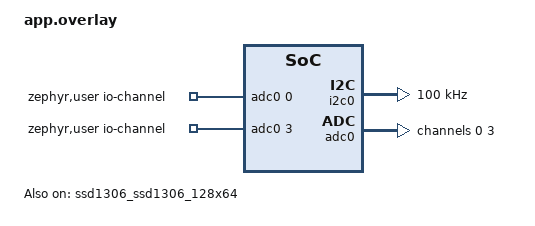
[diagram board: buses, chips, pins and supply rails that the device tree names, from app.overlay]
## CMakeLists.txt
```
cmake_minimum_required(VERSION 3.20.0)
# Must be set before find_package(Zephyr).
set(SHIELD ssd1306_128x64)
find_package(Zephyr REQUIRED HINTS $ENV{ZEPHYR_BASE})
project(zephyr_scene_player)
target_sources(app PRIVATE
    src/main.c
    src/input_thread.c
    src/display_thread.c
    src/scene_draw.c
)
```

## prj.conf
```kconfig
# GPIO/ADC for KY-023 and PRG
CONFIG_GPIO=y
CONFIG_ADC=y
CONFIG_MULTITHREADING=y

# On-board SSD1306 OLED and procedural drawings
CONFIG_I2C=y
CONFIG_DISPLAY=y
CONFIG_SSD1306=y
CONFIG_CHARACTER_FRAMEBUFFER=y
CONFIG_CHARACTER_FRAMEBUFFER_USE_DEFAULT_FONTS=y
CONFIG_HEAP_MEM_POOL_SIZE=2048

# UART terminal (COM13)
CONFIG_CONSOLE=y
CONFIG_PRINTK=y
CONFIG_LOG=y
CONFIG_LOG_DEFAULT_LEVEL=3
```

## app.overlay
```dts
#include <zephyr/dt-bindings/i2c/i2c.h>
#include <zephyr/dt-bindings/adc/adc.h>

/ {
    zephyr,user {
        /* ESP32 ADC1 hardware: GPIO36=channel 0, GPIO39=channel 3. */
        io-channels = <&adc0 0>, <&adc0 3>;
    };
};

/* Proven SSD1306 startup workaround from Example 05/06. */
&i2c0 {
    status = "okay";
    clock-frequency = <I2C_BITRATE_STANDARD>;
};
&ssd1306_ssd1306_128x64 {
    status = "okay";
    zephyr,deferred-init;
};

/* Zephyr adc0 maps to physical ESP32 ADC1. */
&adc0 {
    status = "okay";
    #address-cells = <1>;
    #size-cells = <0>;

    channel@0 {
        reg = <0>;
        zephyr,gain = "ADC_GAIN_1_4";
        zephyr,reference = "ADC_REF_INTERNAL";
        zephyr,acquisition-time = <ADC_ACQ_TIME_DEFAULT>;
        zephyr,resolution = <12>;
    };
    channel@3 {
        reg = <3>;
        zephyr,gain = "ADC_GAIN_1_4";
        zephyr,reference = "ADC_REF_INTERNAL";
        zephyr,acquisition-time = <ADC_ACQ_TIME_DEFAULT>;
        zephyr,resolution = <12>;
    };
};
```

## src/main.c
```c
/* SPDX-License-Identifier: Apache-2.0 */
/* Example 07: six-scene animation player on Heltec WiFi LoRa 32 V2. */
#include <zephyr/kernel.h>
#include <zephyr/device.h>
#include <zephyr/devicetree.h>
#include <zephyr/drivers/i2c.h>
#include <zephyr/drivers/display.h>
#include <zephyr/display/cfb.h>
#include <zephyr/sys/printk.h>
#include <errno.h>
#include "app_events.h"

#define I2C_NODE DT_NODELABEL(i2c0)
#define OLED_NODE DT_CHOSEN(zephyr_display)

#if !DT_HAS_CHOSEN(zephyr_display)
#error "Select the ssd1306_128x64 shield to provide zephyr,display"
#endif
#if !DT_NODE_HAS_PROP(OLED_NODE, zephyr_deferred_init)
#error "OLED must be deferred in app.overlay so I2C can be recovered first"
#endif

static const struct device *const i2c_dev = DEVICE_DT_GET(I2C_NODE);
static const struct device *const oled_dev = DEVICE_DT_GET(OLED_NODE);

/* Input = producer; display = consumer. Both share one statically allocated queue. */
K_MSGQ_DEFINE(app_event_queue, sizeof(struct app_event), 16, 4);

#define INPUT_STACK_SIZE 2048
#define DISPLAY_STACK_SIZE 3072
#define INPUT_PRIORITY 5
#define DISPLAY_PRIORITY 5

K_THREAD_STACK_DEFINE(input_stack, INPUT_STACK_SIZE);
K_THREAD_STACK_DEFINE(display_stack, DISPLAY_STACK_SIZE);
static struct k_thread input_thread_data;
static struct k_thread display_thread_data;

static int init_oled(void)
{
    if (!device_is_ready(i2c_dev)) { return -ENODEV; }

    /* Crucial for the Heltec V2: recovery must precede deferred SSD1306 init. */
    printk("OLED: recovering I2C bus...\n");
    int rc = i2c_recover_bus(i2c_dev);
    if (rc < 0) { return rc; }

    rc = device_init(oled_dev);
    if (rc < 0 || !device_is_ready(oled_dev)) {
        return rc < 0 ? rc : -ENODEV;
    }
    rc = display_set_pixel_format(oled_dev, PIXEL_FORMAT_MONO01);
    if (rc < 0) { return rc; }
    rc = cfb_framebuffer_init(oled_dev);
    if (rc < 0) { return rc; }
    rc = cfb_framebuffer_clear(oled_dev, false);
    if (rc < 0) { return rc; }
    rc = display_blanking_off(oled_dev);
    if (rc < 0) { return rc; }
    printk("OLED: ready\n");
    return 0;
}

int main(void)
{
    printk("\n=================================\n");
    printk(" Example 07: OLED Scene Player\n");
    printk("=================================\n");

    int rc = init_oled();
    if (rc < 0) {
        printk("ERROR: OLED initialization: %d\n", rc);
        return rc;
    }
    rc = input_thread_init();
    if (rc < 0) {
        printk("ERROR: joystick initialization: %d\n", rc);
        return rc;
    }

    /* Display starts first and renders the help screen. */
    k_thread_create(&display_thread_data, display_stack,
                    K_THREAD_STACK_SIZEOF(display_stack), display_thread_entry,
                    NULL, NULL, NULL, DISPLAY_PRIORITY, 0, K_NO_WAIT);
    k_thread_create(&input_thread_data, input_stack,
                    K_THREAD_STACK_SIZEOF(input_stack), input_thread_entry,
                    NULL, NULL, NULL, INPUT_PRIORITY, 0, K_NO_WAIT);

    printk("APP: two threads running; PRG=open/back, SW=play/pause\n");
    return 0;
}
```

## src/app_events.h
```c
/* SPDX-License-Identifier: Apache-2.0 */
#ifndef APP_EVENTS_H_
#define APP_EVENTS_H_

#include <zephyr/kernel.h>

/* Producer: input_thread.c; consumer: display_thread.c. */
enum app_event_type
{
    APP_EVENT_TOGGLE_HELP,       /* Onboard PRG */
    APP_EVENT_CATEGORY_PREVIOUS, /* Joystick up */
    APP_EVENT_CATEGORY_NEXT,     /* Joystick down */
    APP_EVENT_SCENE_PREVIOUS,    /* Joystick left */
    APP_EVENT_SCENE_NEXT,        /* Joystick right */
    APP_EVENT_SELECT,            /* Joystick SW: play / pause / resume */
};

struct app_event
{
    enum app_event_type type;
    uint32_t timestamp_ms;
};

/* Created exactly once in main.c using K_MSGQ_DEFINE(). */
extern struct k_msgq app_event_queue;

int input_thread_init(void);
void input_thread_entry(void* arg1, void* arg2, void* arg3);
void display_thread_entry(void* arg1, void* arg2, void* arg3);

#endif /* APP_EVENTS_H_ */
```

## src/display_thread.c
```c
/* SPDX-License-Identifier: Apache-2.0 */
/* One OLED-owner UI thread. Never blocks for an entire animation. */
#include <zephyr/kernel.h>
#include <zephyr/device.h>
#include <zephyr/devicetree.h>
#include <zephyr/display/cfb.h>
#include <zephyr/sys/printk.h>
#include <errno.h>
#include <stdbool.h>
#include <stddef.h>
#include <stdint.h>
#include <stdio.h>
#include <string.h>
#include "app_events.h"
#include "scene_draw.h"

#define OLED_NODE         DT_CHOSEN(zephyr_display)
#define FRAME_INTERVAL_MS 200 /* ~5 fps; conservative for 100-kHz I2C */
#define MAX_EVENT_WAIT_MS 50
#define SCREEN_W          128

static const struct device* const display = DEVICE_DT_GET(OLED_NODE);

enum page
{
    PAGE_HELP,
    PAGE_BROWSER,
    PAGE_PLAYING,
    PAGE_PAUSED
};

struct ui_state
{
    enum page page;
    enum scene_category category;
    size_t scene_index;
    uint32_t frame;
    int64_t next_frame_ms;
    bool dirty;
};

static uint8_t font_width  = 8U;
static uint8_t font_height = 8U;

#define UI_CHECK(expr)    \
    do                    \
    {                     \
        int rc_ = (expr); \
        if(rc_ < 0)       \
        {                 \
            return rc_;   \
        }                 \
    } while(0)

static int ui_line(int x0, int y0, int x1, int y1)
{
    const struct cfb_position a = { x0, y0 };
    const struct cfb_position b = { x1, y1 };
    return cfb_draw_line(display, &a, &b);
}

/* Width clipping prevents long scene labels from reaching outside the display. */
static int ui_text(const char* str, int x, int y)
{
    char clipped[25];
    size_t max_chars;
    if(x < 0 || x >= SCREEN_W || y < 0 || y + font_height > 64)
    {
        return -EINVAL;
    }
    max_chars = (SCREEN_W - (size_t)x) / font_width;
    if(max_chars >= sizeof(clipped))
    {
        max_chars = sizeof(clipped) - 1U;
    }
    size_t n = strlen(str);
    if(n > max_chars)
    {
        n = max_chars;
    }
    memcpy(clipped, str, n);
    clipped[n] = '\0';
    return cfb_print(display, clipped, (int16_t)x, (int16_t)y);
}

static void select_compact_font(void)
{
    int count = cfb_get_numof_fonts(display);
    for(int i = 0; i < count; ++i)
    {
        uint8_t w = 0, h = 0;
        if(cfb_get_font_size(display, (uint8_t)i, &w, &h) == 0 && w > 0 && w <= 8 &&
           h > 0 && h <= 8 && cfb_framebuffer_set_font(display, (uint8_t)i) == 0)
        {
            font_width  = w;
            font_height = h;
            printk("DISPLAY: CFB font %dx%d\n", w, h);
            return;
        }
    }
    printk("DISPLAY: no compact font found; default font in use\n");
}

static int draw_help(void)
{
    const struct cfb_position center = { 64, 34 };
    UI_CHECK(ui_text("SCENE PLAYER", 0, 0));
    UI_CHECK(ui_line(0, 10, 127, 10));

    UI_CHECK(ui_line(64, 14, 64, 23));
    UI_CHECK(ui_line(64, 14, 58, 20));
    UI_CHECK(ui_line(64, 14, 70, 20));
    UI_CHECK(ui_text("CAT", 77, 15));

    UI_CHECK(ui_line(40, 35, 29, 35));
    UI_CHECK(ui_line(29, 35, 35, 29));
    UI_CHECK(ui_line(29, 35, 35, 41));
    UI_CHECK(ui_text("PREV", 0, 31));

    UI_CHECK(cfb_draw_circle(display, &center, 9));
    UI_CHECK(ui_text("SW", 58, 30));

    UI_CHECK(ui_line(87, 35, 98, 35));
    UI_CHECK(ui_line(98, 35, 92, 29));
    UI_CHECK(ui_line(98, 35, 92, 41));
    UI_CHECK(ui_text("NEXT", 102, 31));

    UI_CHECK(ui_line(64, 45, 64, 53));
    UI_CHECK(ui_line(64, 53, 58, 47));
    UI_CHECK(ui_line(64, 53, 70, 47));
    UI_CHECK(ui_text("CAT", 77, 45));
    UI_CHECK(ui_text("PRG: OPEN/BACK", 0, 56));
    return 0;
}

static enum scene_id selected_scene(const struct ui_state* ui)
{
    return scene_category_get(ui->category, ui->scene_index);
}

static int draw_browser(const struct ui_state* ui)
{
    enum scene_id id = selected_scene(ui);
    char heading[25];
    int n = snprintf(heading, sizeof(heading), "%s %u/%u",
                     scene_category_name(ui->category),
                     (unsigned int)(ui->scene_index + 1U),
                     (unsigned int)scene_category_count(ui->category));
    if(n < 0)
    {
        return -EINVAL;
    }
    UI_CHECK(scene_draw(display, id, 0)); /* Preview first frame */
    UI_CHECK(ui_text(heading, 0, 0));
    UI_CHECK(ui_text(scene_name(id), 0, 56));
    return 0;
}

static int ui_render(const struct ui_state* ui)
{
    UI_CHECK(cfb_framebuffer_clear(display, false));
    switch(ui->page)
    {
        case PAGE_HELP:
            UI_CHECK(draw_help());
            break;
        case PAGE_BROWSER:
            UI_CHECK(draw_browser(ui));
            break;
        case PAGE_PLAYING:
        case PAGE_PAUSED:
            UI_CHECK(scene_draw(display, selected_scene(ui), ui->frame));
            if(ui->page == PAGE_PAUSED)
            {
                UI_CHECK(ui_text("PAUSED", 0, 0));
                UI_CHECK(ui_text("SW: RESUME", 0, 56));
            }
            break;
        default:
            return -EINVAL;
    }
    return cfb_framebuffer_finalize(display);
}

/* A PRG press always returns to the help page from anywhere except help. */
static void handle_event(struct ui_state* ui, enum app_event_type ev)
{
    if(ev == APP_EVENT_TOGGLE_HELP)
    {
        ui->page  = (ui->page == PAGE_HELP) ? PAGE_BROWSER : PAGE_HELP;
        ui->dirty = true;
        return;
    }
    if(ui->page == PAGE_HELP)
    {
        return;
    }

    if(ev == APP_EVENT_SELECT)
    {
        switch(ui->page)
        {
            case PAGE_BROWSER:
                ui->page          = PAGE_PLAYING;
                ui->frame         = 0;
                ui->next_frame_ms = k_uptime_get() + FRAME_INTERVAL_MS;
                break;
            case PAGE_PLAYING:
                ui->page = PAGE_PAUSED;
                break;
            case PAGE_PAUSED:
                ui->page          = PAGE_PLAYING;
                ui->next_frame_ms = k_uptime_get() + FRAME_INTERVAL_MS;
                break;
            default:
                break;
        }
        ui->dirty = true;
        return;
    }
    if(ui->page != PAGE_BROWSER)
    {
        return;
    }

    switch(ev)
    {
        case APP_EVENT_CATEGORY_PREVIOUS:
            ui->category = (enum scene_category)(
            (ui->category + SCENE_CATEGORY_COUNT - 1) % SCENE_CATEGORY_COUNT);
            ui->scene_index = 0;
            ui->dirty       = true;
            break;
        case APP_EVENT_CATEGORY_NEXT:
            ui->category = (enum scene_category)((ui->category + 1) % SCENE_CATEGORY_COUNT);
            ui->scene_index = 0;
            ui->dirty       = true;
            break;
        case APP_EVENT_SCENE_PREVIOUS:
            ui->scene_index =
            (ui->scene_index + scene_category_count(ui->category) - 1U) %
            scene_category_count(ui->category);
            ui->dirty = true;
            break;
        case APP_EVENT_SCENE_NEXT:
            ui->scene_index = (ui->scene_index + 1U) % scene_category_count(ui->category);
            ui->dirty = true;
            break;
        default:
            break;
    }
}

void display_thread_entry(void* arg1, void* arg2, void* arg3)
{
    ARG_UNUSED(arg1);
    ARG_UNUSED(arg2);
    ARG_UNUSED(arg3);
    struct ui_state ui = {
        .page          = PAGE_HELP,
        .category      = SCENE_CAT_SPACE,
        .scene_index   = 0,
        .frame         = 0,
        .next_frame_ms = 0,
        .dirty         = true,
    };
    select_compact_font();
    printk("DISPLAY: scene player started (help screen)\n");

    while(true)
    {
        int64_t now = k_uptime_get();
        int wait_ms = MAX_EVENT_WAIT_MS;
        if(ui.page == PAGE_PLAYING)
        {
            int64_t remaining = ui.next_frame_ms - now;
            if(remaining <= 0)
            {
                wait_ms = 0;
            }
            else if(remaining < wait_ms)
            {
                wait_ms = (int)remaining;
            }
        }

        struct app_event msg;
        if(k_msgq_get(&app_event_queue, &msg, K_MSEC(wait_ms)) == 0)
        {
            handle_event(&ui, msg.type);
        }

        now = k_uptime_get();
        if(ui.page == PAGE_PLAYING && now >= ui.next_frame_ms)
        {
            ui.frame++;
            ui.next_frame_ms = now + FRAME_INTERVAL_MS;
            ui.dirty         = true;
        }
        if(ui.dirty)
        {
            int rc = ui_render(&ui);
            if(rc != 0)
            {
                printk("DISPLAY: render error %d\n", rc);
            }
            ui.dirty = false;
        }
    }
}
```

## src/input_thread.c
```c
/* SPDX-License-Identifier: Apache-2.0 */
/* KY-023 joystick + onboard PRG GPIO0. One event per deflection/press. */
#include <zephyr/kernel.h>
#include <zephyr/device.h>
#include <zephyr/devicetree.h>
#include <zephyr/drivers/adc.h>
#include <zephyr/drivers/gpio.h>
#include <zephyr/sys/printk.h>
#include <errno.h>
#include <stdbool.h>
#include <stdint.h>
#include "app_events.h"

#define USER_NODE DT_PATH(zephyr_user)
#define PRG_NODE DT_ALIAS(sw0)
#define GPIO_NODE DT_NODELABEL(gpio0)

#if !DT_NODE_EXISTS(USER_NODE)
#error "app.overlay must declare zephyr,user { io-channels = <&adc0 0>, <&adc0 3>; };"
#endif
#if !DT_NODE_EXISTS(PRG_NODE)
#error "Board requires sw0 (onboard PRG button) alias"
#endif

/* Connections: VRx=GPIO36 / ADC1_CH0, VRy=GPIO39 / ADC1_CH3, SW=GPIO13. */
#define JOY_SW_PIN 13
#define POLL_MS 50
#define BUTTON_STABLE_SAMPLES 3
#define JOY_LOW 1100
#define JOY_HIGH 3200
#define JOY_CENTER_MIN 1500
#define JOY_CENTER_MAX 2700

/* Change to 1 if your joystick is mounted in the opposite orientation. */
#define JOY_REVERSE_X 0
#define JOY_REVERSE_Y 0

static const struct adc_dt_spec x_axis = ADC_DT_SPEC_GET_BY_IDX(USER_NODE, 0);
static const struct adc_dt_spec y_axis = ADC_DT_SPEC_GET_BY_IDX(USER_NODE, 1);
static const struct gpio_dt_spec prg = GPIO_DT_SPEC_GET(PRG_NODE, gpios);
static const struct device *const port0 = DEVICE_DT_GET(GPIO_NODE);

struct key_debounce {
    bool last_sample;
    bool pressed;
    uint8_t stable_count;
};

static struct key_debounce prg_key;
static struct key_debounce sw_key;

static void send_event(enum app_event_type type)
{
    struct app_event msg = { .type = type, .timestamp_ms = k_uptime_get_32() };
    if (k_msgq_put(&app_event_queue, &msg, K_NO_WAIT) != 0) {
        printk("INPUT: queue full, event %d dropped\n", (int)type);
    }
}

/* True only on the debounced RELEASED->PRESSED transition. */
static bool just_pressed(struct key_debounce *key, bool pressed)
{
    if (key->last_sample != pressed) {
        key->last_sample = pressed;
        key->stable_count = 1;
    } else if (key->stable_count < BUTTON_STABLE_SAMPLES) {
        key->stable_count++;
    }
    if (key->stable_count >= BUTTON_STABLE_SAMPLES && key->pressed != pressed) {
        key->pressed = pressed;
        return pressed;
    }
    return false;
}

static int read_adc(const struct adc_dt_spec *channel, int16_t *result)
{
    int16_t raw = 0;
    struct adc_sequence sequence = {
        .buffer = &raw,
        .buffer_size = sizeof(raw),
    };
    int rc = adc_sequence_init_dt(channel, &sequence);
    if (rc != 0) { return rc; }
    rc = adc_read_dt(channel, &sequence);
    if (rc == 0) { *result = raw; }
    return rc;
}

int input_thread_init(void)
{
    if (!adc_is_ready_dt(&x_axis) || !adc_is_ready_dt(&y_axis) ||
        !gpio_is_ready_dt(&prg) || !device_is_ready(port0)) {
        return -ENODEV;
    }
    int rc = adc_channel_setup_dt(&x_axis);
    if (rc != 0) { return rc; }
    rc = adc_channel_setup_dt(&y_axis);
    if (rc != 0) { return rc; }
    rc = gpio_pin_configure_dt(&prg, GPIO_INPUT);
    if (rc != 0) { return rc; }
    rc = gpio_pin_configure(port0, JOY_SW_PIN, GPIO_INPUT | GPIO_PULL_UP);
    if (rc != 0) { return rc; }
    printk("INPUT: joystick ADC and SW, PRG ready\n");
    return 0;
}

void input_thread_entry(void *arg1, void *arg2, void *arg3)
{
    ARG_UNUSED(arg1);
    ARG_UNUSED(arg2);
    ARG_UNUSED(arg3);

    bool joystick_armed = true;
    int16_t x, y;

    while (true) {
        if (read_adc(&x_axis, &x) == 0 && read_adc(&y_axis, &y) == 0) {
            /* A shared latch rejects diagonal double-events. */
            bool centered = (x >= JOY_CENTER_MIN && x <= JOY_CENTER_MAX &&
                             y >= JOY_CENTER_MIN && y <= JOY_CENTER_MAX);
            if (centered) {
                joystick_armed = true;
            } else if (joystick_armed) {
                enum app_event_type type;
                bool has_event = true;
                int dx = (x > 2048) ? (x - 2048) : (2048 - x);
                int dy = (y > 2048) ? (y - 2048) : (2048 - y);
                if (dx >= dy && (x < JOY_LOW || x > JOY_HIGH)) {
                    bool right = (x > JOY_HIGH);
                    if (JOY_REVERSE_X) { right = !right; }
                    type = right ? APP_EVENT_SCENE_NEXT : APP_EVENT_SCENE_PREVIOUS;
                } else if (y < JOY_LOW || y > JOY_HIGH) {
                    bool down = (y > JOY_HIGH);
                    if (JOY_REVERSE_Y) { down = !down; }
                    type = down ? APP_EVENT_CATEGORY_NEXT : APP_EVENT_CATEGORY_PREVIOUS;
                } else {
                    has_event = false;
                }
                if (has_event) {
                    send_event(type);
                    joystick_armed = false;
                }
            }
        }

        int p = gpio_pin_get_dt(&prg);
        /* GPIO_ACTIVE_LOW in board DTS: logical 1 means pressed. */
        if (p >= 0 && just_pressed(&prg_key, p != 0)) {
            send_event(APP_EVENT_TOGGLE_HELP);
        }

        int s = gpio_pin_get_raw(port0, JOY_SW_PIN);
        /* Physical KY-023 switch connects SW to GND on press. */
        if (s >= 0 && just_pressed(&sw_key, s == 0)) {
            send_event(APP_EVENT_SELECT);
        }
        k_sleep(K_MSEC(POLL_MS));
    }
}
```

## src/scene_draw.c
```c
/* SPDX-License-Identifier: Apache-2.0 */
/* Procedural animation graphics for the Heltec 128x64 SSD1306 OLED. */
#include <zephyr/kernel.h>
#include <zephyr/display/cfb.h>
#include <zephyr/sys/util.h>
#include <errno.h>
#include <stdbool.h>
#include "scene_draw.h"

#define SCREEN_W 128
#define SCREEN_H 64

#define CHECK_DRAW(expr)  \
    do                    \
    {                     \
        int rc_ = (expr); \
        if(rc_ < 0)       \
        {                 \
            return rc_;   \
        }                 \
    } while(0)

static int point(const struct device* dev, int x, int y)
{
    if(x < 0 || x >= SCREEN_W || y < 0 || y >= SCREEN_H)
    {
        return 0;
    }
    const struct cfb_position p = { x, y };
    return cfb_draw_point(dev, &p);
}

/* Clamped endpoints keep moving shapes inside the framebuffer. */
static int line(const struct device* dev, int x0, int y0, int x1, int y1)
{
    x0                          = CLAMP(x0, 0, SCREEN_W - 1);
    x1                          = CLAMP(x1, 0, SCREEN_W - 1);
    y0                          = CLAMP(y0, 0, SCREEN_H - 1);
    y1                          = CLAMP(y1, 0, SCREEN_H - 1);
    const struct cfb_position a = { x0, y0 };
    const struct cfb_position b = { x1, y1 };
    return cfb_draw_line(dev, &a, &b);
}

static int rect(const struct device* dev, int x0, int y0, int x1, int y1)
{
    if(x1 < 0 || x0 >= SCREEN_W || y1 < 0 || y0 >= SCREEN_H)
    {
        return 0;
    }
    const struct cfb_position a = { CLAMP(x0, 0, SCREEN_W - 1), CLAMP(y0, 0, SCREEN_H - 1) };
    const struct cfb_position b = { CLAMP(x1, 0, SCREEN_W - 1), CLAMP(y1, 0, SCREEN_H - 1) };
    return cfb_draw_rect(dev, &a, &b);
}

static int circle(const struct device* dev, int x, int y, int radius)
{
    if(x - radius < 0 || y - radius < 0 || x + radius >= SCREEN_W || y + radius >= SCREEN_H)
    {
        return 0;
    }
    const struct cfb_position center = { x, y };
    return cfb_draw_circle(dev, &center, (uint16_t)radius);
}

static int stars(const struct device* dev, uint32_t frame, int speed)
{
    /* Different y positions and movement speeds produce a parallax effect. */
    for(int i = 0; i < 13; ++i)
    {
        int x = (i * 37 + 117 - (int)((frame * (uint32_t)speed) % 117U)) % 117 + 5;
        int y = 16 + ((i * 19) % 39);
        if(((frame / 4U) + (uint32_t)i) % 3U != 0U)
        {
            CHECK_DRAW(point(dev, x, y));
        }
    }
    return 0;
}

static int rocket_launch(const struct device* dev, uint32_t frame)
{
    int phase = (int)(frame % 48U);
    int y     = 38 - (phase * 28) / 47; /* nose ascends from y=38 to y=10 */

    CHECK_DRAW(stars(dev, frame, 1));
    CHECK_DRAW(line(dev, 5, 60, 45, 60));
    CHECK_DRAW(line(dev, 83, 60, 123, 60));
    CHECK_DRAW(line(dev, 49, 59, 79, 59)); /* Launch pad */

    /* Rocket: pointy nose, capsule, window, fins, alternating flame. */
    CHECK_DRAW(line(dev, 64, y, 57, y + 9));
    CHECK_DRAW(line(dev, 64, y, 71, y + 9));
    CHECK_DRAW(line(dev, 57, y + 9, 57, y + 20));
    CHECK_DRAW(line(dev, 71, y + 9, 71, y + 20));
    CHECK_DRAW(line(dev, 57, y + 20, 71, y + 20));
    CHECK_DRAW(circle(dev, 64, y + 12, 3));
    CHECK_DRAW(line(dev, 57, y + 15, 51, y + 22));
    CHECK_DRAW(line(dev, 51, y + 22, 58, y + 20));
    CHECK_DRAW(line(dev, 71, y + 15, 77, y + 22));
    CHECK_DRAW(line(dev, 77, y + 22, 70, y + 20));
    CHECK_DRAW(line(dev, 61, y + 20, 64, y + 24 + (frame % 2U)));
    CHECK_DRAW(line(dev, 67, y + 20, 64, y + 24 + (frame % 2U)));
    return 0;
}

static int car_driving(const struct device* dev, uint32_t frame)
{
    int bob = ((frame / 2U) % 2U) ? 1 : 0;
    /* Low hills on the horizon. */
    CHECK_DRAW(line(dev, 0, 36, 26, 26));
    CHECK_DRAW(line(dev, 26, 26, 54, 36));
    CHECK_DRAW(line(dev, 54, 36, 79, 30));
    CHECK_DRAW(line(dev, 79, 30, 105, 36));
    CHECK_DRAW(line(dev, 105, 36, 127, 32));
    CHECK_DRAW(line(dev, 0, 54, 127, 54));
    CHECK_DRAW(line(dev, 0, 62, 127, 62));

    /* White road markings move to the left (like an endless road). */
    for(int i = 0; i < 5; ++i)
    {
        int x = ((i * 33 + 128) - (int)((frame * 4U) % 33U));
        if(x < 128)
        {
            CHECK_DRAW(line(dev, x, 58, x + 15, 58));
        }
    }

    /* Car stays near center while the background scrolls. */
    CHECK_DRAW(rect(dev, 38, 43 + bob, 88, 49 + bob));
    CHECK_DRAW(line(dev, 46, 43 + bob, 53, 35 + bob));
    CHECK_DRAW(line(dev, 53, 35 + bob, 74, 35 + bob));
    CHECK_DRAW(line(dev, 74, 35 + bob, 82, 43 + bob));
    CHECK_DRAW(line(dev, 63, 35 + bob, 63, 43 + bob));
    CHECK_DRAW(circle(dev, 49, 50 + bob, 4));
    CHECK_DRAW(circle(dev, 78, 50 + bob, 4));
    return 0;
}

static int rainstorm(const struct device* dev, uint32_t frame)
{
    /* Two overlapping outlined clouds. */
    CHECK_DRAW(line(dev, 18, 28, 18, 23));
    CHECK_DRAW(line(dev, 18, 23, 25, 19));
    CHECK_DRAW(line(dev, 25, 19, 34, 20));
    CHECK_DRAW(line(dev, 34, 20, 41, 15));
    CHECK_DRAW(line(dev, 41, 15, 54, 16));
    CHECK_DRAW(line(dev, 54, 16, 62, 23));
    CHECK_DRAW(line(dev, 62, 23, 62, 28));
    CHECK_DRAW(line(dev, 18, 28, 62, 28));
    CHECK_DRAW(line(dev, 56, 30, 67, 23));
    CHECK_DRAW(line(dev, 67, 23, 81, 23));
    CHECK_DRAW(line(dev, 81, 23, 86, 17));
    CHECK_DRAW(line(dev, 86, 17, 99, 18));
    CHECK_DRAW(line(dev, 99, 18, 110, 25));
    CHECK_DRAW(line(dev, 110, 25, 110, 30));
    CHECK_DRAW(line(dev, 56, 30, 110, 30));

    for(int i = 0; i < 19; ++i)
    {
        int x = 4 + (i * 29) % 119;
        int y = 33 + ((i * 11 + (int)(frame * 4U)) % 25);
        CHECK_DRAW(line(dev, x, y, x - 2, y + 4));
    }
    CHECK_DRAW(line(dev, 0, 61, 127, 61));
    /* Animated concentric ripple hints. */
    int ripple = (int)(frame % 5U) + 2;
    CHECK_DRAW(line(dev, 28 - ripple, 60, 28 + ripple, 60));
    CHECK_DRAW(line(dev, 90 - ripple, 60, 90 + ripple, 60));
    return 0;
}

static int sunrise(const struct device* dev, uint32_t frame)
{
    int phase = (int)(frame % 80U);
    int sun_y = 47 - (phase * 23) / 79;

    CHECK_DRAW(circle(dev, 64, sun_y, 9));
    CHECK_DRAW(line(dev, 64, sun_y - 15, 64, sun_y - 12));
    CHECK_DRAW(line(dev, 49, sun_y, 52, sun_y));
    CHECK_DRAW(line(dev, 76, sun_y, 79, sun_y));
    CHECK_DRAW(line(dev, 53, sun_y - 11, 56, sun_y - 8));
    CHECK_DRAW(line(dev, 75, sun_y - 11, 72, sun_y - 8));
    CHECK_DRAW(line(dev, 0, 56, 34, 31));
    CHECK_DRAW(line(dev, 34, 31, 59, 52));
    CHECK_DRAW(line(dev, 52, 56, 92, 25));
    CHECK_DRAW(line(dev, 92, 25, 127, 56));
    CHECK_DRAW(line(dev, 0, 57, 127, 57));
    CHECK_DRAW(line(dev, 0, 62, 127, 62));
    return 0;
}

static int bouncing_ball(const struct device* dev, uint32_t frame)
{
    int phase    = (int)(frame % 32U);
    int up       = (phase <= 16) ? phase : 32 - phase;
    int jump     = up * (32 - up) * 25 / 256;
    int x        = 12 + (int)((frame * 2U) % 102U);
    int y        = 50 - jump;
    int shadow_r = 8 - jump / 6;

    CHECK_DRAW(line(dev, 0, 57, 127, 57));
    CHECK_DRAW(line(dev, 0, 58, 127, 58));
    CHECK_DRAW(line(dev, x - shadow_r, 60, x + shadow_r, 60));
    CHECK_DRAW(circle(dev, x, y, 6));
    CHECK_DRAW(circle(dev, x - 2, y - 2, 1));
    /* Little wall to bounce past. */
    CHECK_DRAW(rect(dev, 114, 45, 124, 56));
    return 0;
}

static int space_adventure(const struct device* dev, uint32_t frame)
{
    int bob        = (int)((frame / 3U) % 4U) - 1;
    int asteroid_x = 120 - (int)((frame * 2U) % 122U);

    CHECK_DRAW(stars(dev, frame, 3));
    /* Small distant planet. */
    CHECK_DRAW(circle(dev, 104, 25, 9));
    CHECK_DRAW(line(dev, 91, 26, 117, 22));

    if(asteroid_x >= 9 && asteroid_x <= 119)
    {
        CHECK_DRAW(circle(dev, asteroid_x, 51, 6));
        CHECK_DRAW(point(dev, asteroid_x - 2, 50));
        CHECK_DRAW(point(dev, asteroid_x + 2, 53));
    }

    /* Ship with a rear thruster and animated exhaust. */
    CHECK_DRAW(line(dev, 49, 36 + bob, 18, 26 + bob));
    CHECK_DRAW(line(dev, 49, 36 + bob, 18, 46 + bob));
    CHECK_DRAW(line(dev, 18, 26 + bob, 23, 36 + bob));
    CHECK_DRAW(line(dev, 23, 36 + bob, 18, 46 + bob));
    CHECK_DRAW(circle(dev, 35, 36 + bob, 3));
    CHECK_DRAW(line(dev, 19, 32 + bob, 12 - (frame % 4U), 32 + bob));
    CHECK_DRAW(line(dev, 19, 40 + bob, 12 - (frame % 4U), 40 + bob));
    return 0;
}

const char* scene_name(enum scene_id scene)
{
    static const char* const names[SCENE_COUNT] = {
        "ROCKET LAUNCH", "CAR DRIVING",   "RAINSTORM",
        "SUNRISE",       "BOUNCING BALL", "SPACE ADVENTURE"
    };
    return ((unsigned int)scene < SCENE_COUNT) ? names[scene] : "UNKNOWN";
}

const char* scene_category_name(enum scene_category category)
{
    static const char* const names[SCENE_CATEGORY_COUNT] = { "SPACE", "MOTION", "NATURE" };
    return ((unsigned int)category < SCENE_CATEGORY_COUNT) ? names[category] : "UNKNOWN";
}

size_t scene_category_count(enum scene_category category)
{
    return ((unsigned int)category < SCENE_CATEGORY_COUNT) ? 2U : 0U;
}

enum scene_id scene_category_get(enum scene_category category, size_t index)
{
    static const enum scene_id entries[SCENE_CATEGORY_COUNT][2] = {
        { SCENE_ROCKET_LAUNCH, SCENE_SPACE_ADVENTURE },
        { SCENE_CAR_DRIVING, SCENE_BOUNCING_BALL },
        { SCENE_RAINSTORM, SCENE_SUNRISE },
    };
    if((unsigned int)category >= SCENE_CATEGORY_COUNT || index >= 2U)
    {
        return SCENE_COUNT;
    }
    return entries[category][index];
}

int scene_draw(const struct device* display, enum scene_id scene, uint32_t frame)
{
    if(display == NULL)
    {
        return -EINVAL;
    }
    switch(scene)
    {
        case SCENE_ROCKET_LAUNCH:
            return rocket_launch(display, frame);
        case SCENE_CAR_DRIVING:
            return car_driving(display, frame);
        case SCENE_RAINSTORM:
            return rainstorm(display, frame);
        case SCENE_SUNRISE:
            return sunrise(display, frame);
        case SCENE_BOUNCING_BALL:
            return bouncing_ball(display, frame);
        case SCENE_SPACE_ADVENTURE:
            return space_adventure(display, frame);
        default:
            return -EINVAL;
    }
}
```

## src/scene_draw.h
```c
/* SPDX-License-Identifier: Apache-2.0 */
#ifndef SCENE_DRAW_H_
#define SCENE_DRAW_H_

#include <zephyr/device.h>
#include <stddef.h>
#include <stdint.h>

/* Six independent, procedurally animated, 1-bit OLED scenes. */
enum scene_id
{
    SCENE_ROCKET_LAUNCH,
    SCENE_CAR_DRIVING,
    SCENE_RAINSTORM,
    SCENE_SUNRISE,
    SCENE_BOUNCING_BALL,
    SCENE_SPACE_ADVENTURE,
    SCENE_COUNT
};

enum scene_category
{
    SCENE_CAT_SPACE,
    SCENE_CAT_MOTION,
    SCENE_CAT_NATURE,
    SCENE_CATEGORY_COUNT
};

const char* scene_name(enum scene_id scene);
const char* scene_category_name(enum scene_category category);
size_t scene_category_count(enum scene_category category);
enum scene_id scene_category_get(enum scene_category category, size_t index);

/* Draw scene into the current CFB buffer. Does not clear/finalize buffer. */
int scene_draw(const struct device* display, enum scene_id scene, uint32_t frame);

#endif /* SCENE_DRAW_H_ */
```
